# SA3_SS0_SA_UL_0_REGS register map
Vendor: Texas Instruments
Peripheral module from a debugger description file (folder am62P).
Registers are 32-bit, read-only, reset 0x0 unless marked. A register's access mark holds for its fields unless they carry their own. Offsets are as the file gives them; lines under a group give offsets from that group; [hi:lo] are bit positions; {n}, {i} and the like mark numbered series; 'fields as' and 'values as' point back to an identical list; <NAME> marks a mode.

## SA3_SS0_SA_UL_0_REGS
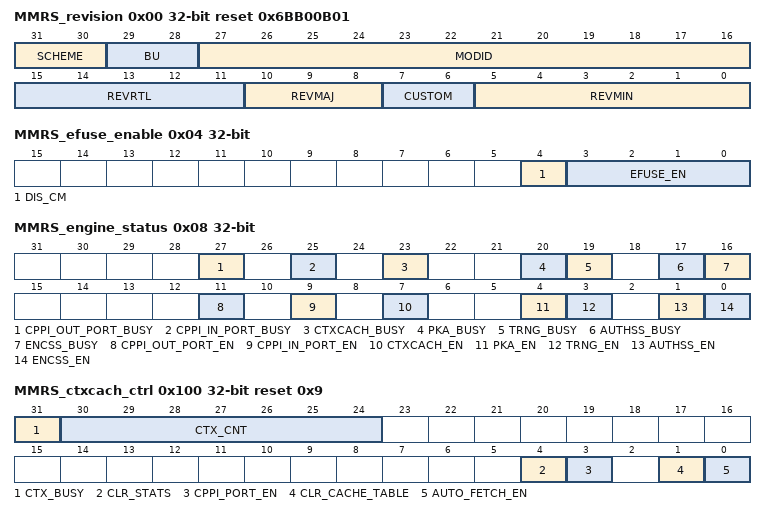
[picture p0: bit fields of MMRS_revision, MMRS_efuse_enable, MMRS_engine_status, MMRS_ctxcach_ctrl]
0x00 MMRS_revision reset 0x6BB00B01 — Version and Identification Register
  [31:30] SCHEME
  [29:28] BU — Business Unit
  [27:16] MODID — Module ID
  [15:11] REVRTL — RTL revision
  [10:8] REVMAJ — Major revision
  [7:6] CUSTOM — Custom revision
  [5:0] REVMIN — Minor Revision
0x04 MMRS_efuse_enable — The efuse_enable register contains the disable of the countermeasure/dpa feature, and the enable for the AES,SHA,SM3,SM4,PKA crypto cores in the device
  [4] DIS_CM — Disable for the countermeasure feature which is driven by Security Manager of the SMS IP. Value of 1 means feature is disabled.
  [3:0] EFUSE_EN — Efuse crypto enable must be set high to enable crypto core, bit3=sm3_sm4_en, bit2=pka_en, bit1=encr_drbg_en, bit0=sha_en
0x08 MMRS_engine_status — The engine_status register contains the enable and busy status for every crypto core
  [27] CPPI_OUT_PORT_BUSY — PSI output port busy status bit
  [25] CPPI_IN_PORT_BUSY — PSI input port busy status bit
  [23] CTXCACH_BUSY — ContextCache module busy status bit
  [20] PKA_BUSY — PKA module busy status bit
  [19] TRNG_BUSY — Random number generator module busy status bit
  [17] AUTHSS_BUSY — Authentication module busy status bit
  [16] ENCSS_BUSY — Encryption module busy status bit
  [11] CPPI_OUT_PORT_EN — Enable indicator for the output streaming interface
  [9] CPPI_IN_PORT_EN — Enable indicator for the input streaming interface
  [7] CTXCACH_EN — Enable indicator for context cache engine
  [4] PKA_EN — Enable indicator for PKA engine
  [3] TRNG_EN — Enable indicator for TRNG engine
  [1] AUTHSS_EN — Enable indicator for authentication engine
  [0] ENCSS_EN — Enable indicator for encryption engine
0x14 MMRS_cppi_flowid rw — The flowid register is no longer used as the DMA software info word 2 must carry this information
  [7:0] CPPI_FLOWID — cppi default flow id
0x1C MMRS_default_eng_id rw reset 0x14 — The default_eng_id contains the first engine only if default engine id code is in the DMA software info word 0
  [4:0] DEFAULT_ENG_ID — default engine id
0x100 MMRS_ctxcach_ctrl access per field reset 0x9 — The ctxcach_ctrl contains some control and status of the context cache engine
  [31] CTX_BUSY ro — context busy
  [30:24] CTX_CNT ro — context counts
  [4] CLR_STATS rw — clear stats
  [3] CPPI_PORT_EN rw — enable cppi ctxcach port
  [1] CLR_CACHE_TABLE ro — clear cache table
  [0] AUTO_FETCH_EN ro — enable auto fetch
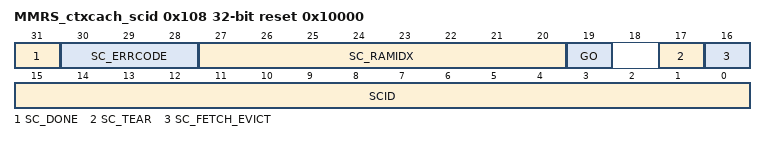
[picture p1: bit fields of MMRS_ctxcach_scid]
0x108 MMRS_ctxcach_scid access per field reset 0x10000 — The ctxcach_scid register is no longer used as context operation is fully under hardware control
  [31] SC_DONE ro — done bit indicator
  [30:28] SC_ERRCODE ro — pass / error code result
  [27:20] SC_RAMIDX ro — ram index result
  [19] GO rw — execute
  [17] SC_TEAR rw — 1:tear
  [16] SC_FETCH_EVICT ro — always read 1:evict
  [15:0] SCID rw — SCID for mmr based evict
0x10C MMRS_ctxcach_misscnt — The ctxcach_misscnt contains the number of how many misses that trigger context fetch
  [31:0] CTX_MISSCNT — cache miss counter
